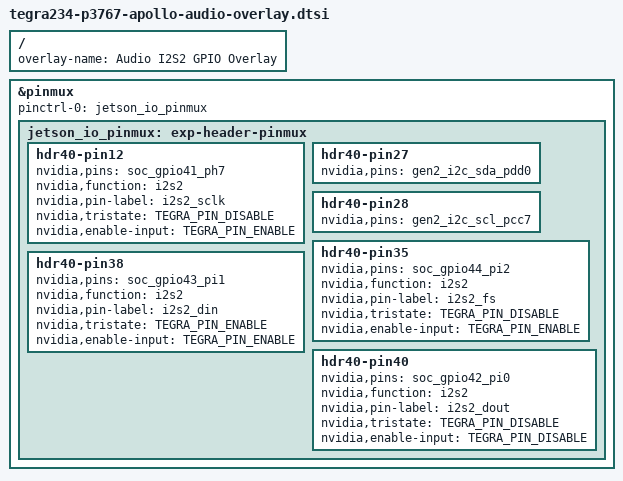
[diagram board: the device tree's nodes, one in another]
/*
 * Copyright (c) 2021-2023, NVIDIA CORPORATION.  All rights reserved.
 *
 * This program is free software; you can redistribute it and/or modify it
 * under the terms and conditions of the GNU General Public License,
 * version 2, as published by the Free Software Foundation.
 *
 * This program is distributed in the hope it will be useful, but WITHOUT
 * ANY WARRANTY; without even the implied warranty of MERCHANTABILITY or
 * FITNESS FOR A PARTICULAR PURPOSE.  See the GNU General Public License for
 * more details.
 *
 * You should have received a copy of the GNU General Public License
 * along with this program.  If not, see <http://www.gnu.org/licenses/>.
 */

#include <dt-bindings/pinctrl/pinctrl-tegra.h>
#include <dt-common/jetson/tegra234-p3767-0000-common.h>
/ {
	overlay-name = "Audio I2S2 GPIO Overlay";
    compatible = JETSON_COMPATIBLE;

	fragment@0 {
		target = <&pinmux>;
		__overlay__ {
			pinctrl-names = "default";
			pinctrl-0 = <&jetson_io_pinmux>;
			jetson_io_pinmux: exp-header-pinmux {
				hdr40-pin12 {
					nvidia,pins = "soc_gpio41_ph7";
					nvidia,function = "i2s2";
					nvidia,pin-label = "i2s2_sclk";
					nvidia,tristate = <TEGRA_PIN_DISABLE>;
					nvidia,enable-input = <TEGRA_PIN_ENABLE>;
				};
				hdr40-pin27 {
					nvidia,pins = "gen2_i2c_sda_pdd0";
				};
				hdr40-pin28 {
					nvidia,pins = "gen2_i2c_scl_pcc7";
				};
				hdr40-pin35 {
					nvidia,pins = "soc_gpio44_pi2";
					nvidia,function = "i2s2";
					nvidia,pin-label = "i2s2_fs";
					nvidia,tristate = <TEGRA_PIN_DISABLE>;
					nvidia,enable-input = <TEGRA_PIN_ENABLE>;
				};
				hdr40-pin38 {
					nvidia,pins = "soc_gpio43_pi1";
					nvidia,function = "i2s2";
					nvidia,pin-label = "i2s2_din";
					nvidia,tristate = <TEGRA_PIN_ENABLE>;
					nvidia,enable-input = <TEGRA_PIN_ENABLE>;
				};
				hdr40-pin40 {
					nvidia,pins = "soc_gpio42_pi0";
					nvidia,function = "i2s2";
					nvidia,pin-label = "i2s2_dout";
					nvidia,tristate = <TEGRA_PIN_DISABLE>;
					nvidia,enable-input = <TEGRA_PIN_DISABLE>;
				};
			};
		};
	};
};
